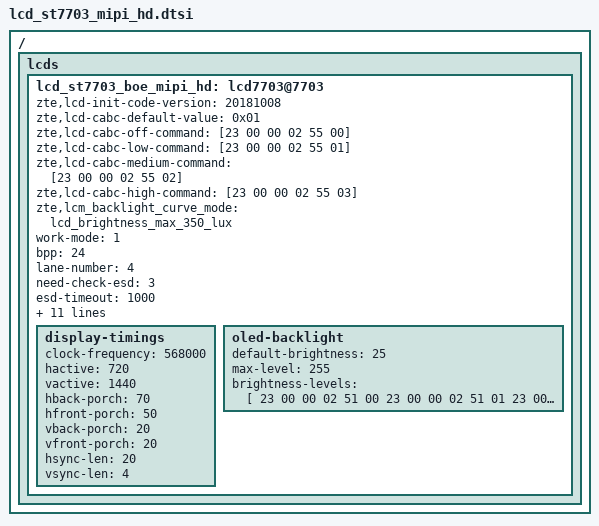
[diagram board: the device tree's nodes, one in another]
/ { lcds {
	lcd_st7703_boe_mipi_hd: lcd7703@7703 {
		zte,lcd-init-code-version = "20181008";
		zte,lcd-cabc-default-value = <0x01>;
		zte,lcd-cabc-off-command = [23 00 00 02 55 00];
		zte,lcd-cabc-low-command = [23 00 00 02 55 01];
		zte,lcd-cabc-medium-command = [23 00 00 02 55 02];
		zte,lcd-cabc-high-command = [23 00 00 02 55 03];
		zte,lcm_backlight_curve_mode = "lcd_brightness_max_350_lux";

		work-mode = <1>;
		bpp = <24>;
		lane-number = <4>;

		need-check-esd = <3>;
		esd-timeout = <1000>;
		esd-check-reg = <0x09>;
		esd-return-code = <0x80>;

		fps = <60>;
		panel-name = "lcd_st7703_boe_mipi_hd";

		power-on-sequence = <
					50  1  10
					4   1  5
					5   1  5
					50  1  10
					50  0  10
					50  1  120
					>;
		power-off-sequence = <
					5   0  5
					4   0  5
					50  0  20
					>;

		init-data = [
			39 00 00 04 B9 F1 12 83
			39 00 00 1C BA 33 81 05 F9 0E 0E 20 00 00 00 00 00 00 00 44 25 00 91 0A 00 00 02 4F 11 03 02 37
			23 00 00 02 B8 76
			39 00 00 0B B3 0C 10 05 05 03 FF 00 00 00 00
			39 00 00 0A C0 73 73 50 50 C0 00 08 50 00
			23 00 00 02 BC 4F
			23 00 00 02 CC 0B
			23 00 00 02 B4 80
			39 00 00 04 B2 F0 12 A0
			39 00 00 0F E3 07 07 0B 0B 03 0B 00 00 00 00 6F 00 C0 10
			39 00 00 0D C1 53 C0 26 26 77 F1 FF FF EE EE EE EE
			39 00 00 06 C6 02 40 CF 7F 00
			39 00 00 03 B5 14 14
			39 00 00 04 BF 02 11 00
			39 00 00 40 E9 82 10 09 00 00 C1 89 12 31 23 47 87 C1 89 47 2A 00 00 0C 00 00 00 00 00 0C 00 00 00 88 20 46 02 88 88 88 88 88 88 FF 88 31 57 13 88 88 88 88 88 88 FF 00 00 00 00 00 00 00 00 00 00 00 00 00
			39 00 00 3E EA 00 1A 00 00 00 00 02 00 00 00 00 00 8F 13 31 75 88 88 88 88 88 88 F8 8F 02 20 64 88 88 88 88 88 88 F8 23 00 00 00 00 00 00 00 00 00 00 00 00 00 00 00 00 00 00 00 00 00 00 00 00 00 00
			39 00 00 23 E0 00 03 07 28 2F 38 36 36 05 0B 0D 10 12 10 12 12 18 00 03 07 28 2F 38 36 36 05 0B 0D 10 12 10 12 12 18
			23 00 00 02 C7 B0
			39 00 00 04 C8 10 01 02
			23 00 00 02 51 00
			23 00 00 02 53 24
			23 00 00 02 55 02
			23 00 00 02 5E 04
			13 78 00 01 11
			13 32 00 01 29
			];
		sleep-in = [
			13 0A 00 01 28
			13 78 00 01 10
			];
		sleep-out = [
			13 78 00 01 11
			13 64 00 01 29
			];

		display-timings {
			clock-frequency = <568000>;
			hactive = <720>;
			vactive = <1440>;
			hback-porch = <70>;
			hfront-porch = <50>;
			vback-porch = <20>;
			vfront-porch = <20>;
			hsync-len = <20>;
			vsync-len = <4>;
		};

		oled-backlight {
			default-brightness = <25>;
			max-level = <255>;
			brightness-levels = [
				23 00 00 02 51 00
				23 00 00 02 51 01
				23 00 00 02 51 02
				23 00 00 02 51 03
				23 00 00 02 51 04
				23 00 00 02 51 05
				23 00 00 02 51 06
				23 00 00 02 51 07
				23 00 00 02 51 08
				23 00 00 02 51 09
				23 00 00 02 51 0A
				23 00 00 02 51 0B
				23 00 00 02 51 0C
				23 00 00 02 51 0D
				23 00 00 02 51 0E
				23 00 00 02 51 0F
				23 00 00 02 51 10
				23 00 00 02 51 11
				23 00 00 02 51 12
				23 00 00 02 51 13
				23 00 00 02 51 14
				23 00 00 02 51 15
				23 00 00 02 51 16
				23 00 00 02 51 17
				23 00 00 02 51 18
				23 00 00 02 51 19
				23 00 00 02 51 1A
				23 00 00 02 51 1B
				23 00 00 02 51 1C
				23 00 00 02 51 1D
				23 00 00 02 51 1E
				23 00 00 02 51 1F
				23 00 00 02 51 20
				23 00 00 02 51 21
				23 00 00 02 51 22
				23 00 00 02 51 23
				23 00 00 02 51 24
				23 00 00 02 51 25
				23 00 00 02 51 26
				23 00 00 02 51 27
				23 00 00 02 51 28
				23 00 00 02 51 29
				23 00 00 02 51 2A
				23 00 00 02 51 2B
				23 00 00 02 51 2C
				23 00 00 02 51 2D
				23 00 00 02 51 2E
				23 00 00 02 51 2F
				23 00 00 02 51 30
				23 00 00 02 51 31
				23 00 00 02 51 32
				23 00 00 02 51 33
				23 00 00 02 51 34
				23 00 00 02 51 35
				23 00 00 02 51 36
				23 00 00 02 51 37
				23 00 00 02 51 38
				23 00 00 02 51 39
				23 00 00 02 51 3A
				23 00 00 02 51 3B
				23 00 00 02 51 3C
				23 00 00 02 51 3D
				23 00 00 02 51 3E
				23 00 00 02 51 3F
				23 00 00 02 51 40
				23 00 00 02 51 41
				23 00 00 02 51 42
				23 00 00 02 51 43
				23 00 00 02 51 44
				23 00 00 02 51 45
				23 00 00 02 51 46
				23 00 00 02 51 47
				23 00 00 02 51 48
				23 00 00 02 51 49
				23 00 00 02 51 4A
				23 00 00 02 51 4B
				23 00 00 02 51 4C
				23 00 00 02 51 4D
				23 00 00 02 51 4E
				23 00 00 02 51 4F
				23 00 00 02 51 50
				23 00 00 02 51 51
				23 00 00 02 51 52
				23 00 00 02 51 53
				23 00 00 02 51 54
				23 00 00 02 51 55
				23 00 00 02 51 56
				23 00 00 02 51 57
				23 00 00 02 51 58
				23 00 00 02 51 59
				23 00 00 02 51 5A
				23 00 00 02 51 5B
				23 00 00 02 51 5C
				23 00 00 02 51 5D
				23 00 00 02 51 5E
				23 00 00 02 51 5F
				23 00 00 02 51 60
				23 00 00 02 51 61
				23 00 00 02 51 62
				23 00 00 02 51 63
				23 00 00 02 51 64
				23 00 00 02 51 65
				23 00 00 02 51 66
				23 00 00 02 51 67
				23 00 00 02 51 68
				23 00 00 02 51 69
				23 00 00 02 51 6A
				23 00 00 02 51 6B
				23 00 00 02 51 6C
				23 00 00 02 51 6D
				23 00 00 02 51 6E
				23 00 00 02 51 6F
				23 00 00 02 51 70
				23 00 00 02 51 71
				23 00 00 02 51 72
				23 00 00 02 51 73
				23 00 00 02 51 74
				23 00 00 02 51 75
				23 00 00 02 51 76
				23 00 00 02 51 77
				23 00 00 02 51 78
				23 00 00 02 51 79
				23 00 00 02 51 7A
				23 00 00 02 51 7B
				23 00 00 02 51 7C
				23 00 00 02 51 7D
				23 00 00 02 51 7E
				23 00 00 02 51 7F
				23 00 00 02 51 80
				23 00 00 02 51 81
				23 00 00 02 51 82
				23 00 00 02 51 83
				23 00 00 02 51 84
				23 00 00 02 51 85
				23 00 00 02 51 86
				23 00 00 02 51 87
				23 00 00 02 51 88
				23 00 00 02 51 89
				23 00 00 02 51 8A
				23 00 00 02 51 8B
				23 00 00 02 51 8C
				23 00 00 02 51 8D
				23 00 00 02 51 8E
				23 00 00 02 51 8F
				23 00 00 02 51 90
				23 00 00 02 51 91
				23 00 00 02 51 92
				23 00 00 02 51 93
				23 00 00 02 51 94
				23 00 00 02 51 95
				23 00 00 02 51 96
				23 00 00 02 51 97
				23 00 00 02 51 98
				23 00 00 02 51 99
				23 00 00 02 51 9A
				23 00 00 02 51 9B
				23 00 00 02 51 9C
				23 00 00 02 51 9D
				23 00 00 02 51 9E
				23 00 00 02 51 9F
				23 00 00 02 51 A0
				23 00 00 02 51 A1
				23 00 00 02 51 A2
				23 00 00 02 51 A3
				23 00 00 02 51 A4
				23 00 00 02 51 A5
				23 00 00 02 51 A6
				23 00 00 02 51 A7
				23 00 00 02 51 A8
				23 00 00 02 51 A9
				23 00 00 02 51 AA
				23 00 00 02 51 AB
				23 00 00 02 51 AC
				23 00 00 02 51 AD
				23 00 00 02 51 AE
				23 00 00 02 51 AF
				23 00 00 02 51 B0
				23 00 00 02 51 B1
				23 00 00 02 51 B2
				23 00 00 02 51 B3
				23 00 00 02 51 B4
				23 00 00 02 51 B5
				23 00 00 02 51 B6
				23 00 00 02 51 B7
				23 00 00 02 51 B8
				23 00 00 02 51 B9
				23 00 00 02 51 BA
				23 00 00 02 51 BB
				23 00 00 02 51 BC
				23 00 00 02 51 BD
				23 00 00 02 51 BE
				23 00 00 02 51 BF
				23 00 00 02 51 C0
				23 00 00 02 51 C1
				23 00 00 02 51 C2
				23 00 00 02 51 C3
				23 00 00 02 51 C4
				23 00 00 02 51 C5
				23 00 00 02 51 C6
				23 00 00 02 51 C7
				23 00 00 02 51 C8
				23 00 00 02 51 C9
				23 00 00 02 51 CA
				23 00 00 02 51 CB
				23 00 00 02 51 CC
				23 00 00 02 51 CD
				23 00 00 02 51 CE
				23 00 00 02 51 CF
				23 00 00 02 51 D0
				23 00 00 02 51 D1
				23 00 00 02 51 D2
				23 00 00 02 51 D3
				23 00 00 02 51 D4
				23 00 00 02 51 D5
				23 00 00 02 51 D6
				23 00 00 02 51 D7
				23 00 00 02 51 D8
				23 00 00 02 51 D9
				23 00 00 02 51 DA
				23 00 00 02 51 DB
				23 00 00 02 51 DC
				23 00 00 02 51 DD
				23 00 00 02 51 DE
				23 00 00 02 51 DF
				23 00 00 02 51 E0
				23 00 00 02 51 E1
				23 00 00 02 51 E2
				23 00 00 02 51 E3
				23 00 00 02 51 E4
				23 00 00 02 51 E5
				23 00 00 02 51 E6
				23 00 00 02 51 E7
				23 00 00 02 51 E8
				23 00 00 02 51 E9
				23 00 00 02 51 EA
				23 00 00 02 51 EB
				23 00 00 02 51 EC
				23 00 00 02 51 ED
				23 00 00 02 51 EE
				23 00 00 02 51 EF
				23 00 00 02 51 F0
				23 00 00 02 51 F1
				23 00 00 02 51 F2
				23 00 00 02 51 F3
				23 00 00 02 51 F4
				23 00 00 02 51 F5
				23 00 00 02 51 F6
				23 00 00 02 51 F7
				23 00 00 02 51 F8
				23 00 00 02 51 F9
				23 00 00 02 51 FA
				23 00 00 02 51 FB
				23 00 00 02 51 FC
				23 00 00 02 51 FD
				23 00 00 02 51 FE
				23 00 00 02 51 FF
			];
		};
	};
};};

